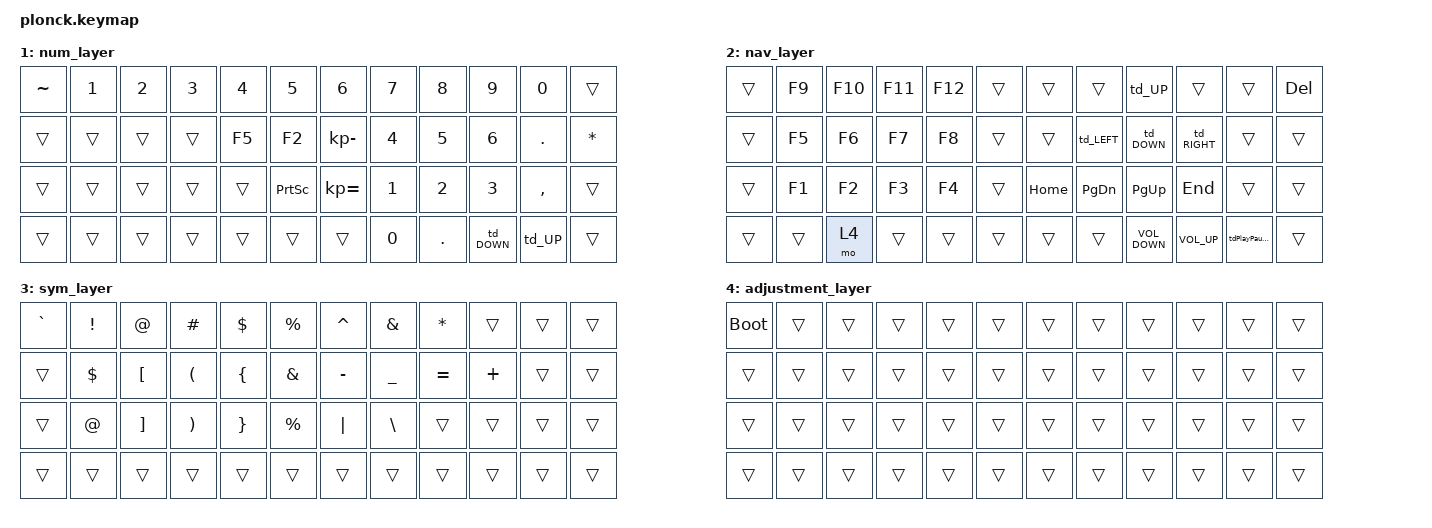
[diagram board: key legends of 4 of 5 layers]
/*
 * Copyright (c) 2021 swampmonster
 *
 * SPDX-License-Identifier: MIT
 */

#include <behaviors.dtsi>
#include <dt-bindings/zmk/keys.h>
// #include <dt-bindings/zmk/bt.h>

// Autoshift Macro
#define AS(keycode) &as LS(keycode) keycode


&caps_word {
  continue-list = <UNDERSCORE MINUS>;
};

/ {

    behaviors {
      hm: homerow_mods {
          compatible = "zmk,behavior-hold-tap";
          label = "HOMEROW_MODS";
          #binding-cells = <2>;
          tapping-term-ms = <100>;                        // <---[[produces tap if held longer than tapping-term-ms]]
          quick-tap-ms = <200>;
          flavor = "tap-preferred";
          bindings = <&kp>, <&kp>;
          retro-tap;
      };

      td_LEFT: tap_dance_0 {
          compatible = "zmk,behavior-tap-dance";
          label = "TAP_DANCE_0";
          #binding-cells = <0>;
          tapping-term-ms = <200>;
          bindings = <&kp LEFT>, <&kp LC(LEFT)>;
      };

      td_DOWN: tap_dance_1 {
          compatible = "zmk,behavior-tap-dance";
          label = "TAP_DANCE_1";
          #binding-cells = <0>;
          tapping-term-ms = <200>;
          bindings = <&kp DOWN>, <&kp LC(DOWN)>;
      };

      td_UP: tap_dance_2 {
          compatible = "zmk,behavior-tap-dance";
          label = "TAP_DANCE_2";
          #binding-cells = <0>;
          tapping-term-ms = <200>;
          bindings = <&kp UP>, <&kp LC(UP)>;
      };

      td_RIGHT: tap_dance_3 {
          compatible = "zmk,behavior-tap-dance";
          label = "TAP_DANCE_3";
          #binding-cells = <0>;
          tapping-term-ms = <200>;
          bindings = <&kp RIGHT>, <&kp LC(RIGHT)>;
      };

      tdPlayPauseNext: tap_dance_play_next {
          compatible = "zmk,behavior-tap-dance";
          label = "TAP_DANCE_PLAYPAUSE_NEXT";
          #binding-cells = <0>;
          tapping-term-ms = <200>;
          bindings = <&kp C_PP>, <&kp C_NEXT>;
      };

      as: auto_shift {
            compatible = "zmk,behavior-hold-tap";
            label = "AUTO_SHIFT";
            #binding-cells = <2>;
            tapping_term_ms = <250>;
            quick_tap_ms = <125>;
            flavor = "tap-preferred";
            bindings = <&kp>, <&kp>;
            global-quick-tap;

        };
    };

    combos {
        compatible = "zmk,combos";

        combo_qw {
            timeout-ms = <75>;
            key-positions = <1 2>;
            bindings = <&as LS(RA(W)) RA(W)>;
        };
        combo_as {
            timeout-ms = <75>;
            key-positions = <13 14>;
            bindings = <&as LS(RA(A)) RA(A)>;
        };
        combo_op {
            timeout-ms = <75>;
            key-positions = <9 10>;
            bindings = <&as  LS(RA(O)) RA(O)>;
        };
        combo_brace {
            timeout-ms = <75>;
            key-positions = <15 16>;
            bindings = <&as RBRC LBRC>;
        };

        combo_brkt {
            timeout-ms = <75>;
            key-positions = <14 15>;
            bindings = <&as RBKT LBKT>;
        };
        combo_paren {
            timeout-ms = <75>;
            key-positions = <16 17>;
            bindings = <&as RPAR LPAR>;
        };

        combo_underscore {
            timeout-ms = <75>;
            key-positions = <19 20>;
            bindings = <&kp UNDER>;
        };
        combo_minus {
            timeout-ms = <75>;
            key-positions = <18 19>;
            bindings = <&as PLUS MINUS>;
        };
        combo_equal {
            timeout-ms = <75>;
            key-positions = <20 21>;
            bindings = <&kp EQUAL>;
        };

        combo_plus {
            timeout-ms = <75>;
            key-positions = <21 22>;
            bindings = <&kp PLUS>;
        };
        combo_colon {
            timeout-ms = <75>;
            key-positions = <22 23>;
            bindings = <&kp EQUAL>;
        };
      };



	keymap {
		compatible = "zmk,keymap";

      default_layer {
        bindings = <
                &gresc                  AS(Q)       AS(W)       AS(E)       AS(R)         AS(T)         AS(Y)          AS(U)             AS(I)              AS(O)      AS(P)               &kp BSPC
                &kp TAB                 AS(A)       AS(S)       AS(D)       AS(F)         AS(G)         AS(H)          AS(J)             AS(K)              AS(L)      AS(SEMI)            AS(SQT)
                &mt LSHFT &caps_word    AS(Z)       AS(X)       AS(C)       AS(V)         AS(B)         AS(N)          AS(M)             AS(COMMA)          AS(DOT)    AS(FSLH)            &kp RET
                &trans                  &kp LGUI    &kp LALT    &kp LCTRL   &lt 1 LPAR    &lt 2 SPACE   &lt 2 SPACE    &lt 3 LBRC        &kp RALT           &td_LEFT   &td_RIGHT           &trans
        >;
      };

      // default_layer {
      //   bindings = <
      //           &gresc                  AS(Q)       &kp W         &kp E           &kp R          &kp T          &kp Y          &kp U          &kp I         &kp O         &kp P                &kp BSPC
      //           &kp TAB                 &hm LSHIFT A          &hm LALT S    &hm LCTRL D     &hm LSHFT F    &kp G          &kp H          &hm RSHFT J    &hm RCTRL K   &hm RALT L    &kp SEMI             &kp SQT
      //           &mt LSHFT &caps_word    &kp Z       &kp X         &kp C           &kp V          &kp B          &kp N          &kp M          &kp COMMA     &kp DOT       &kp FSLH             &kp RET
      //           &trans                  &kp LGUI    &kp LALT      &kp LCTRL       &lt 1 LPAR     &lt 2 SPACE    &lt 2 SPACE    &lt 3 LBRC     &kp RALT      &kp RCTRL     &tdPlayPauseNext     &trans
      //   >;
      // };


    num_layer {
      bindings = <
            &kp TILDE  &kp N1  &kp N2   &kp N3   &kp N4   &kp N5     &kp N6        &kp N7  &kp N8     &kp N9    &kp N0         &trans
            &trans     &trans  &trans   &trans   &kp F5   &kp F2     &kp KP_MINUS  &kp N4  &kp N5     &kp N6    &kp DOT    &kp ASTRK
            &trans     &trans  &trans   &trans   &trans   &kp PSCRN  &kp KP_EQUAL  &kp N1  &kp N2     &kp N3    &kp COMMA   &trans
            &trans     &trans  &trans   &trans   &trans   &trans     &trans        &kp N0  &kp DOT  &td_DOWN  &td_UP         &trans
      >;
    };

    nav_layer {
      // &kp C_VOL_DOWN  &kp C_VOL_UP  &tdPlayNext

            //  esc     Q        W        E        R         T         Y          U           I                   O                 P                   BSPC
			bindings = <
                &trans  &kp F9   &kp F10  &kp F11  &kp F12   &trans    &trans     &trans      &td_UP              &trans             &trans             &kp DEL
                &trans  &kp F5   &kp F6   &kp F7   &kp F8    &trans    &trans     &td_LEFT    &td_DOWN            &td_RIGHT          &trans             &trans
                &trans  &kp F1   &kp F2   &kp F3   &kp F4    &trans    &kp HOME   &kp PG_DN   &kp PG_UP           &kp END            &trans             &trans
                &trans  &trans   &mo 4    &trans   &trans    &trans    &trans     &trans      &kp C_VOLUME_DOWN   &kp C_VOLUME_UP    &tdPlayPauseNext   &trans
			>;
		};


    // nav_layer {
		// 	bindings = <
    //             &bootloader &trans &trans &trans &trans &trans &trans   &trans    &trans    &trans    &trans &kp DEL
    //             &trans      &trans &trans &trans &trans &trans &kp LEFT &kp DOWN  &kp UP    &kp RIGHT &trans &trans
    //             &trans      &trans &trans &trans &trans &trans &kp HOME &kp PG_DN &kp PG_UP &kp END   &trans &trans
    //             &trans      &trans &trans &trans &trans &trans &mo 4 &trans &trans    &trans    &trans &trans
		// 	>;
		// };
    sym_layer {
      //    esc        Q            W         E          R            T            Y           U            I             O         P       BSPC
      bindings = <
            &kp GRAVE  &kp EXCL     &kp AT    &kp HASH   &kp DOLLAR   &kp PRCNT    &kp CARET   &kp AMPS     &kp ASTRK     &trans    &trans  &trans
            &trans     &kp DOLLAR   &kp LBKT  &kp LPAR   &kp LBRC     &kp AMPS     &kp MINUS   &kp UNDER    &kp EQUAL     &kp PLUS  &trans  &trans
            &trans     &kp AT       &kp RBKT  &kp RPAR   &kp RBRC     &kp PRCNT    &kp PIPE    &kp BSLH     &trans        &trans    &trans  &trans
            &trans     &trans       &trans    &trans     &trans       &trans       &trans      &trans       &trans        &trans    &trans  &trans
      >;
    };


     adjustment_layer {
        bindings = <
            &bootloader  &trans   &trans   &trans  &trans  &trans  &trans  &trans  &trans  &trans  &trans  &trans
            &trans       &trans   &trans   &trans  &trans  &trans  &trans  &trans  &trans  &trans  &trans  &trans
            &trans       &trans   &trans   &trans  &trans  &trans  &trans  &trans  &trans  &trans  &trans  &trans
            &trans       &trans   &trans   &trans  &trans  &trans  &trans  &trans  &trans  &trans  &trans  &trans
        >;
    };

    // old_adjustment_layer {
    //         bindings = <
    //             &bt BT_CLR &bt BT_SEL 0 &bt BT_SEL 1 &bt BT_SEL 2 &bt BT_SEL 3 &trans &trans &trans &trans &trans &trans &trans
    //             &bt BT_PRV &bt BT_NXT &trans &trans &trans &trans &trans &trans &trans &trans &trans &trans
    //             &trans &trans &trans &trans    &trans &trans &trans &trans &trans &trans &trans &trans
    //             &trans    &trans    &trans    &trans    &trans   &trans   &trans &trans &trans &trans &trans &trans
    //         >;
    //     };
	};
};
